# EPROM_1 register map
Vendor: Texas Instruments
Peripheral module from a debugger description file (folder msp430).
Registers are 8-bit, read-write, reset 0x0 unless marked. A register's access mark holds for its fields unless they carry their own. Offsets are as the file gives them; lines under a group give offsets from that group; [hi:lo] are bit positions; {n}, {i} and the like mark numbered series; 'fields as' and 'values as' point back to an identical list; <NAME> marks a mode.

## EPROM
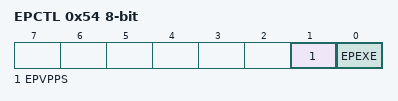
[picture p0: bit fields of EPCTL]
0x54 EPCTL — EPROM Control
  [1] EPVPPS, [0] EPEXE
